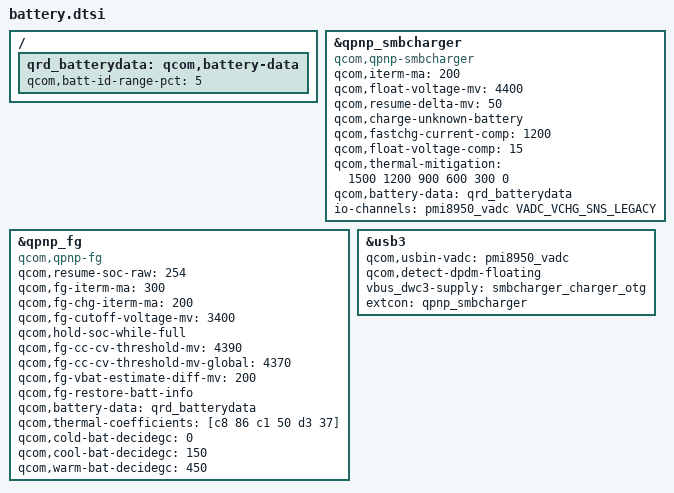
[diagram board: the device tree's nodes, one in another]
/ {
	qrd_batterydata: qcom,battery-data {
		qcom,batt-id-range-pct = <5>;
		#include "../common/batterydata/batterydata-qrd-sunwoda-4v4-4100mah.dtsi"
		#include "../common/batterydata/batterydata-qrd-sunwoda-ATL-4v4-4100mah.dtsi"
		#include "../common/batterydata/batterydata-qrd-coslight-4v4-4100mah.dtsi"
		#include "../common/batterydata/batterydata-qrd-desay-lisheng-4v4-4100mah.dtsi"
		#include "../common/batterydata/batterydata-qrd-desay-4v4-4100mah.dtsi"
	};

};

&qpnp_smbcharger {
	compatible = "qcom,qpnp-smbcharger";

	qcom,iterm-ma = <200>;
    qcom,float-voltage-mv = <4400>;
	qcom,resume-delta-mv = <50>;
	qcom,charge-unknown-battery;
	qcom,fastchg-current-comp = <1200>;
	qcom,float-voltage-comp = <15>;
	/delete-property/ qcom,autoadjust-vfloat;
    qcom,thermal-mitigation = <1500 1200 900 600 300 0>;
    qcom,battery-data = <&qrd_batterydata>;
	/delete-property/ qcom,parallel-usb-min-current-ma;
	/delete-property/ qcom,parallel-usb-9v-min-current-ma;
	/delete-property/ qcom,parallel-allowed-lowering-ma;
	/delete-property/ qcom,external-typec;
	/delete-property/ qcom,typec-psy-name;
	io-channels = <&pmi8950_vadc VADC_VCHG_SNS_LEGACY>;
	io-channel-names = "vchg_sns";
    status = "okay";
};

&qpnp_fg {
	compatible = "qcom,qpnp-fg";

    /delete-property/ qcom,resume-soc;
	qcom,resume-soc-raw = <254>;
	qcom,fg-iterm-ma = <300>;
	qcom,fg-chg-iterm-ma = <200>;
	qcom,fg-cutoff-voltage-mv = <3400>;
	qcom,hold-soc-while-full;
	qcom,fg-cc-cv-threshold-mv = <4390>;
	qcom,fg-cc-cv-threshold-mv-global = <4370>;
	qcom,fg-vbat-estimate-diff-mv = <200>;
	qcom,fg-restore-batt-info;
    qcom,battery-data = <&qrd_batterydata>;
    qcom,thermal-coefficients = [c8 86 c1 50 d3 37];
	qcom,cold-bat-decidegc = <0>;
	qcom,cool-bat-decidegc = <150>;
	qcom,warm-bat-decidegc = <450>;
    status = "okay";
};

&usb3 {
	qcom,usbin-vadc = <&pmi8950_vadc>;
	qcom,detect-dpdm-floating;
	vbus_dwc3-supply = <&smbcharger_charger_otg>;
	extcon = <&qpnp_smbcharger>;
};
